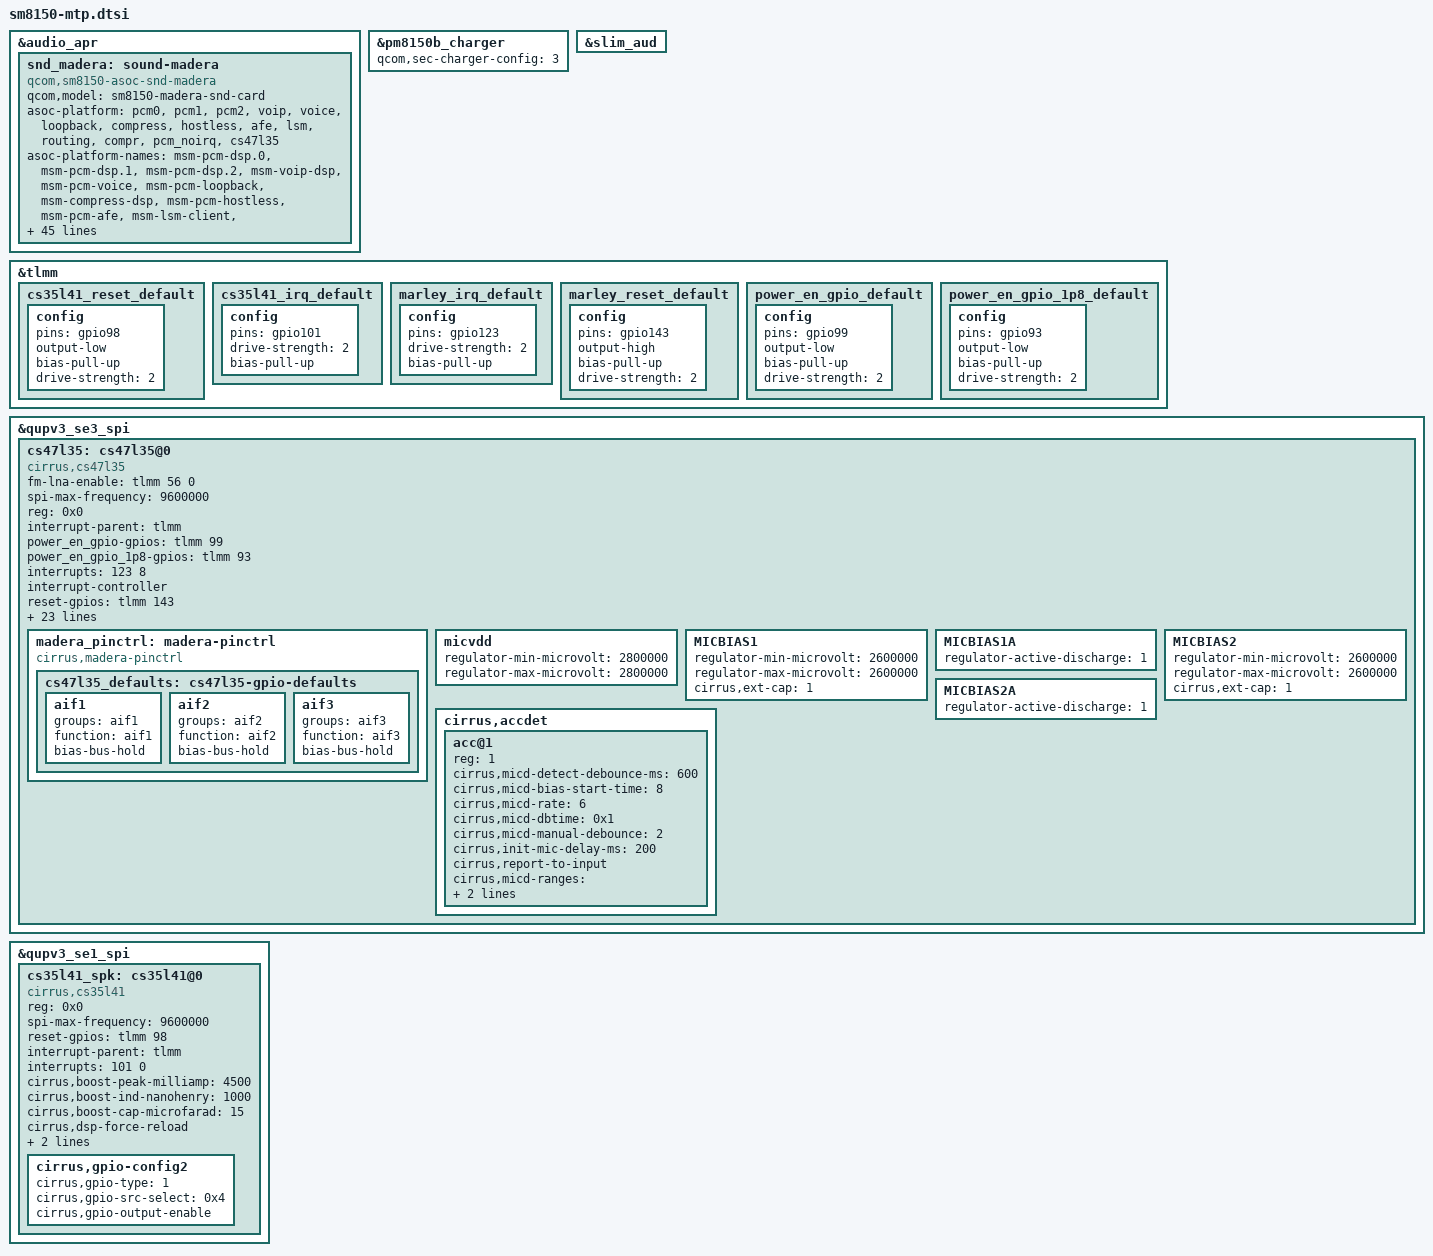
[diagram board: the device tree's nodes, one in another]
&audio_apr {
        snd_madera: sound-madera {
                compatible = "qcom,sm8150-asoc-snd-madera";
                qcom,model = "sm8150-madera-snd-card";

                asoc-platform = <&pcm0>, <&pcm1>, <&pcm2>, <&voip>, <&voice>,
                                <&loopback>, <&compress>, <&hostless>,
                                <&afe>, <&lsm>, <&routing>, <&compr>,
                                <&pcm_noirq>, <&cs47l35>;
                asoc-platform-names = "msm-pcm-dsp.0", "msm-pcm-dsp.1",
                                "msm-pcm-dsp.2", "msm-voip-dsp",
                                "msm-pcm-voice", "msm-pcm-loopback",
                                "msm-compress-dsp", "msm-pcm-hostless",
                                "msm-pcm-afe", "msm-lsm-client",
                                "msm-pcm-routing", "msm-compr-dsp",
                                "msm-pcm-dsp-noirq","cs47l35-codec";
                asoc-cpu = <&dai_hdmi>, <&dai_dp>,
                                <&dai_mi2s0>, <&dai_mi2s1>,
                                <&dai_mi2s2>, <&dai_mi2s3>,
                                <&dai_mi2s4>, <&dai_pri_auxpcm>,
                                <&dai_sec_auxpcm>, <&dai_tert_auxpcm>,
                                <&dai_quat_auxpcm>, <&dai_quin_auxpcm>,
                                <&sb_0_rx>, <&sb_0_tx>, <&sb_1_rx>, <&sb_1_tx>,
                                <&sb_2_rx>, <&sb_2_tx>, <&sb_3_rx>, <&sb_3_tx>,
                                <&sb_4_rx>, <&sb_4_tx>, <&sb_5_tx>,
                                <&afe_pcm_rx>, <&afe_pcm_tx>, <&afe_proxy_rx>,
                                <&afe_proxy_tx>, <&incall_record_rx>,
                                <&incall_record_tx>, <&incall_music_rx>,
                                <&incall_music_2_rx>, <&sb_5_rx>, <&sb_6_rx>,
                                <&sb_7_rx>, <&sb_7_tx>, <&sb_8_tx>,
                                <&usb_audio_rx>, <&usb_audio_tx>,
                                <&dai_pri_tdm_rx_0>, <&dai_pri_tdm_tx_0>,
                                <&dai_sec_tdm_rx_0>, <&dai_sec_tdm_tx_0>,
                                <&dai_tert_tdm_rx_0>, <&dai_tert_tdm_tx_0>,
                                <&dai_quat_tdm_rx_0>, <&dai_quat_tdm_tx_0>,
                                <&dai_quin_tdm_rx_0>, <&dai_quin_tdm_tx_0>;
                asoc-cpu-names = "msm-dai-q6-hdmi.8",  "msm-dai-q6-dp.24608",
                                "msm-dai-q6-mi2s.0", "msm-dai-q6-mi2s.1",
                                "msm-dai-q6-mi2s.2", "msm-dai-q6-mi2s.3",
                                "msm-dai-q6-mi2s.4", "msm-dai-q6-auxpcm.1",
                                "msm-dai-q6-auxpcm.2", "msm-dai-q6-auxpcm.3",
                                "msm-dai-q6-auxpcm.4", "msm-dai-q6-auxpcm.5",
                                "msm-dai-q6-dev.16384", "msm-dai-q6-dev.16385",
                                "msm-dai-q6-dev.16386", "msm-dai-q6-dev.16387",
                                "msm-dai-q6-dev.16388", "msm-dai-q6-dev.16389",
                                "msm-dai-q6-dev.16390", "msm-dai-q6-dev.16391",
                                "msm-dai-q6-dev.16392", "msm-dai-q6-dev.16393",
                                "msm-dai-q6-dev.16395", "msm-dai-q6-dev.224",
                                "msm-dai-q6-dev.225", "msm-dai-q6-dev.241",
                                "msm-dai-q6-dev.240", "msm-dai-q6-dev.32771",
                                "msm-dai-q6-dev.32772", "msm-dai-q6-dev.32773",
                                "msm-dai-q6-dev.32770", "msm-dai-q6-dev.16394",
                                "msm-dai-q6-dev.16396", "msm-dai-q6-dev.16398",
                                "msm-dai-q6-dev.16399", "msm-dai-q6-dev.16401",
                                "msm-dai-q6-dev.28672", "msm-dai-q6-dev.28673",
                                "msm-dai-q6-tdm.36864", "msm-dai-q6-tdm.36865",
                                "msm-dai-q6-tdm.36880", "msm-dai-q6-tdm.36881",
                                "msm-dai-q6-tdm.36896", "msm-dai-q6-tdm.36897",
                                "msm-dai-q6-tdm.36912", "msm-dai-q6-tdm.36913",
                                "msm-dai-q6-tdm.36928", "msm-dai-q6-tdm.36929";
                fsa4480-i2c-handle = <&fsa4480>;
        };
};


&pm8150b_charger {
	qcom,sec-charger-config = <3>;
};


&slim_aud {
        /delete-property/ status;
        /delete-node/ msm_dai_slim;
};

&tlmm {
     cs35l41_reset_default: cs35l41_reset_default {
             config {
                    pins = "gpio98";
                    output-low;
                    bias-pull-up;
                    drive-strength = <2>;
            };
     };

     cs35l41_irq_default: cs35l41_irq_default {
            config {
                    pins = "gpio101";
                    drive-strength = <2>;
                    bias-pull-up;
           };
     };

    marley_irq_default: marley_irq_default {
        config {
            pins = "gpio123";
            drive-strength = <2>;
            bias-pull-up;
        };
    };

    marley_reset_default: marley_reset_default {
        config {
            pins = "gpio143";
            output-high;
            bias-pull-up;
            drive-strength = <2>;
        };
    };

    power_en_gpio_default: power_en_gpio_default {
                config {
                        pins = "gpio99";
                        output-low;
                        bias-pull-up;
                        drive-strength = <2>;
        };
    };
    power_en_gpio_1p8_default:power_en_gpio_1p8_default {
                config {
                        pins = "gpio93";
                        output-low;
                        bias-pull-up;
                        drive-strength = <2>;
        };
    };
};


&qupv3_se3_spi {
    status = "okay";
    cs47l35: cs47l35@0 {
        compatible = "cirrus,cs47l35";
        fm-lna-enable = <&tlmm 56 0>;
        spi-max-frequency = <9600000>;
        reg = <0x0>;
        interrupt-parent = <&tlmm>;
        power_en_gpio-gpios = <&tlmm 99 0>;
        power_en_gpio_1p8-gpios = <&tlmm 93 0>;
        interrupts = <123 8>;
        interrupt-controller;
        #interrupt-cells = <2>;
        reset-gpios = <&tlmm 143 0>;
        clock-names = "madera_mclk1";
        clocks = <&clock_rpmh RPMH_LN_BB_CLK2>;
        pinctrl-names = "default","power_en_gpio","enable","disable","power_en_gpio_1p8","active";
        pinctrl-0 = <&marley_irq_default &marley_reset_default>;
        pinctrl-1 = <&power_en_gpio_default>;
        pinctrl-2 = <&madera_rtc_mclk2_enable>;
        pinctrl-3 = <&madera_rtc_mclk2_disable>;
        pinctrl-4 = <&power_en_gpio_1p8_default>;
        pinctrl-5 = <&cs47l35_defaults>;
        AVDD-supply = <&pm8150l_l8>;
        DBVDD1-supply = <&pm8150l_l8>;
        DBVDD2-supply = <&pm8150l_l8>;
        CPVDD-supply = <&pm8150l_l8>;
        CPVDD1-supply = <&pm8150l_l8>;
        DCVDD-supply = <&dummy_vreg>;
        SPKVDD-supply = <&dummy_vreg>;
                fsa4480-mic-supply = <&pm8150l_bob>;
                madera,rgltr-min-voltage = <3700000>;//3008000
                madera,rgltr-max-voltage = <3700000>;
                madera,rgltr-load-current = <2000000>;


        fsa4480-i2c-handle = <&fsa4480>;
        gpio-controller;
        #gpio-cells = <2>;

        cirrus,inmode =   <
                        0 0 1 1
                        0 0 0 0
        >;
        cirrus,out-mono = <0 0 0 0 0 0>;

        madera_pinctrl: madera-pinctrl {
                compatible = "cirrus,madera-pinctrl";
                        cs47l35_defaults: cs47l35-gpio-defaults {
                        aif1 {
                        groups = "aif1";
                        function = "aif1";
                        bias-bus-hold;
                        };

                        aif2 {
                        groups = "aif2";
                        function = "aif2";
                        bias-bus-hold;
                        };

                        aif3 {
                        groups = "aif3";
                        function = "aif3";
                        bias-bus-hold;
                        };
               };
        };

        micvdd {
                regulator-min-microvolt = <2800000>;
                regulator-max-microvolt = <2800000>;
        };

        MICBIAS1 {
                regulator-min-microvolt = <2600000>;
                regulator-max-microvolt = <2600000>;
                cirrus,ext-cap = <1>;
        };
        MICBIAS1A {
                regulator-active-discharge = <1>;
        };

        MICBIAS2 {
                regulator-min-microvolt = <2600000>;
                regulator-max-microvolt = <2600000>;
                cirrus,ext-cap = <1>;
        };
        MICBIAS2A {
                regulator-active-discharge = <1>;
        };

        cirrus,accdet {
            #address-cells = <1>;
            #size-cells = <0>;

            acc@1 {
                reg = <1>;

                cirrus,micd-detect-debounce-ms = <600>;
                cirrus,micd-bias-start-time = <8>;
                cirrus,micd-rate = <6>;
                cirrus,micd-dbtime = <0x1>;
                cirrus,micd-manual-debounce = <2>;
                cirrus,init-mic-delay-ms = <200>;
                cirrus,report-to-input;
                cirrus,micd-ranges = <
                    100 226  /* HEADSETHOOK  */
                    150 582  /* VOICE_ASSIST */
                    295 115  /* VOLUME_UP    */
                    1257 114 /* VOLUME_DOWN  */
                >;
                cirrus,micd-configs = < 1 0 1 0 0
                                        1 0 1 0 0>;
               /* cirrus,gpsw = <1>;*/
            };
       };
    };
};

&qupv3_se1_spi {
        status = "okay";
        cs35l41_spk: cs35l41@0 {
           compatible = "cirrus,cs35l41";
           reg = <0x0>;
           spi-max-frequency = <9600000>;
           reset-gpios = <&tlmm 98 0>;
           interrupt-parent = <&tlmm>;
           interrupts = <101 0>;
           interrupt-names = "amp_spk_irq";
           /* cirrus,right-channel-amp; */
           cirrus,boost-peak-milliamp = <4500>;
           cirrus,boost-ind-nanohenry = <1000>;
           cirrus,boost-cap-microfarad = <15>;
           cirrus,dsp-force-reload;
           cirrus,asp-sdout-hiz = <0x3>;
           pinctrl-names = "default";
           pinctrl-0 = <&cs35l41_reset_default>;
           cirrus,gpio-config2 {
           cirrus,gpio-type = <1>; /* 0 indicate gpio, 1 indicate interrupt */
           cirrus,gpio-src-select = <0x4>;
           cirrus,gpio-output-enable;
           };
        };
};

